# MCASP3_CFG register map
Vendor: Texas Instruments
Registers are 32-bit, read-write, reset values left out (the file's numbers can be read two ways) unless marked. A register's access mark holds for its fields unless they carry their own. Offsets are as the file gives them; [hi:lo] are bit positions; {n}, {i} and the like mark numbered series; 'fields as' and 'values as' point back to an identical list.

## MCASP3_CFG (part 2 of 2)
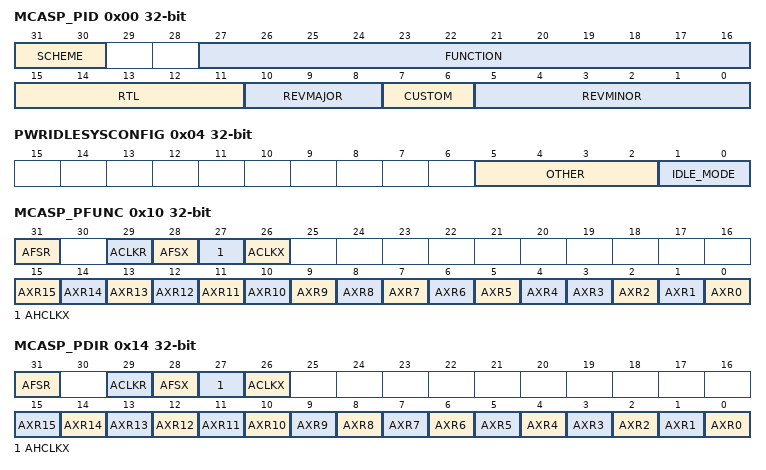
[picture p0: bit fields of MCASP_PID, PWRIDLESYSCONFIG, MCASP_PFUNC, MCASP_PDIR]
0x00 MCASP_PID ro — Peripheral identification register
  [31:30] SCHEME — Scheme. Distinguishes between old scheme and current.
  [27:16] FUNCTION — MCASP. Indicates a software-compatible module family.
  [15:11] RTL — RTL version.
  [10:8] REVMAJOR — Major revision number.
  [7:6] CUSTOM — Non-custom. Indicates a special version for a given device.
  [5:0] REVMINOR — Minor revision number.
0x04 PWRIDLESYSCONFIG access per field — Power idle module configuration register.
  [5:2] OTHER rw — Reserved for future expansion
  [1:0] IDLE_MODE rw — 0x0: Force-idle mode 0x1: No-idle mode 0x2: Smart-idle mode - default state 0x3: Reserved
0x10 MCASP_PFUNC — Specifies the function of the pins as either a MCASP pin or a GPIO pin
  [31] AFSR — Determines if AFSR pin (device level MCASPi_fsr signal) functions as MCASP or GPIO.
    0=Pin_functions_as_MCASP_pin; 1=Pin_functions_as_GIO_pin
  [29] ACLKR — Determines if ACLKR pin (device level MCASPi_aclkr signal) functions as MCASP or GPIO.
    0=Pin_functions_as_MCASP_pin; 1=Pin_functions_as_GIO_pin
  [28] AFSX — Determines if AFSX pin (device level MCASPi_fsx signal) functions as MCASP or GPIO.
    0=GPIO (Pin functions as MCASP pin); 1=Pin_functions_as_GIO_pin
  [27] AHCLKX — Determines if AHCLKX pin (device level MCASPi_ahclkx signal) functions as MCASP or GPIO.
    values as AFSX
  [26] ACLKX — Determines if ACLKX pin (device level MCASPi_aclkx signal) functions as MCASP or GPIO.
    values as AFSX
  [n] AXR{n} (n=4..15) — Determines if AXR{n} pin (device level MCASPx_axr[{n}] signal) functions as MCASP or GPIO.
    0=Pin_functions_as_MCASP_pin; 1=Pin_functions_as_GIO_pin
  [3] AXR3 — Determines if AXR3 pin (device level MCASPi_axr[3] signal) functions as MCASP or GPIO.
    0=Pin_functions_as_MCASP_pin; 1=Pin_functions_as_GIO_pin
  [2] AXR2 — Determines if AXR2 pin (device level MCASPi_axr[2] signal) functions as MCASP or GPIO.
    0=Pin_functions_as_MCASP_pin; 1=Pin_functions_as_GIO_pin
  [1] AXR1 — Determines if AXR1 pin (device level MCASPi_axr[1] signal) functions as MCASP or GPIO.
    0=Pin_functions_as_MCASP_pin; 1=Pin_functions_as_GIO_pin
  [0] AXR0 — Determines if AXR0 pin (device level MCASPi_axr[0] signal) functions as MCASP or GPIO.
    values as AFSX
0x14 MCASP_PDIR — Pin direction register - specifies the direction of the MCASP pins as either an input or an output pin.
  [31] AFSR — Determines if AFSR pin (device level MCASPi_fsr signal) functions as an input or output.
    0=Input; 1=Output
  [29] ACLKR — Determines if ACLKR pin (device level MCASPi_aclkr signal) functions as an input or output.
    0=Input; 1=Output
  [28] AFSX — Determines if AFSX pin (device level MCASPi_fsx signal) functions as an input or output.
    0=OUTPUT (Input); 1=Output
  [27] AHCLKX — Determines if AHCLKX pin (device level MCASPi_ahclkx signal) functions as an input or output.
    0=OUTPUT (Input); 1=Output
  [26] ACLKX — Determines if ACLKX pin (device level MCASPi_aclkx signal) functions as an input or output.
    0=OUTPUT (Input); 1=Output
  [n] AXR{n} (n=1..15) — Determines if AXR{n} pin (device level MCASPi_axr[{n}] signal) functions as an input or output.
    0=Input; 1=Output
  [0] AXR0 — Determines if AXR0 pin (device level MCASPi_axr[0] signal) functions as an input or output.
    0=OUTPUT (Input); 1=Output
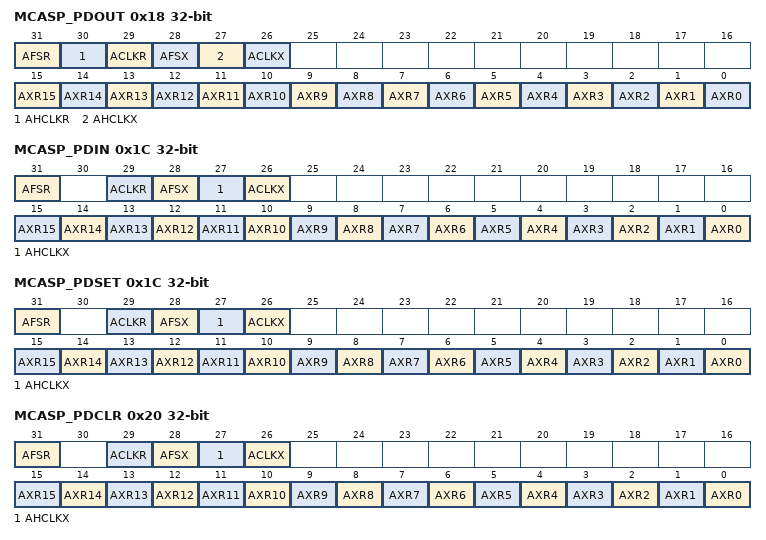
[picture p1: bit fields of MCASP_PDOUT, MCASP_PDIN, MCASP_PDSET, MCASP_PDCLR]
0x18 MCASP_PDOUT — Pin data output register - holds a value for data out at all times, and may be read back at all times. The value held by is not affected by writing to and . However, the data value in is driven out onto the MCASP pin only if the corresponding bit in is set to 1 (GPIO function) and the corresponding bit in is set to 1 (output).
  [31] AFSR — Determines drive on AFSR output pin when the correspondingMCASP_PFUNC[31] and MCASP_PDIR[31] bits are set to 1.
    0=The_pin_drives_low; 1=The_pin_drives_high
  [30] AHCLKR — Determines drive on AHCLKR output pin when the correspondingMCASP_PFUNC[30] and MCASP_PDIR[30] bits are set to 1.
    0=The_pin_drives_low; 1=The_pin_drives_high
  [29] ACLKR — Determines drive on ACLKR output pin when the correspondingMCASP_PFUNC[29] and MCASP_PDIR[29] bits are set to 1
    0=The_pin_drives_low; 1=The_pin_drives_high
  [28] AFSX — Determines drive on AFSX output pin when the correspondingMCASP_PFUNC[28] and MCASP_PDIR[28] bits are set to 1.
    0=DRV1 (The pin drives low.); 1=The_pin_drives_high
  [27] AHCLKX — Determines drive on AHCLKX output pin when the correspondingMCASP_PFUNC[27] and MCASP_PDIR[27] bits are set to 1.
    0=DRV1 (The pin drives low.); 1=The_pin_drives_high
  [26] ACLKX — Determines drive on ACLKX output pin when the correspondingMCASP_PFUNC[26] and MCASP_PDIR[26] bits are set to 1
    0=DRV1 (The pin drives low.); 1=The_pin_drives_high
  [n] AXR{n} (n=1..15) — Determines drive on AXR{n} output pin when the correspondingMCASP_PFUNC[{n}] and MCASP_PDIR[{n}] bits are set to 1.
    0=The_pin_drives_low; 1=The_pin_drives_high
  [0] AXR0 — Determines drive on AXR0 output pin when the correspondingMCASP_PFUNC[0] and MCASP_PDIR[0] bits are set to 1.
    0=DRV1 (The pin drives low.); 1=The_pin_drives_high
0x1C MCASP_PDIN ro — Pin data input register - holds the state of all the MCASP pins. allows reading the actual value of the pin, regardless of the state of and .
  [31] AFSR — Logic level on AFSR pin (device level MCASPi_fsr signal).
    0=Pin_is_logic_low; 1=Pin_is_logic_high
  [29] ACLKR — Logic level on ACLKR pin (device level MCASPi_aclkr signal).
    0=Pin_is_logic_low; 1=Pin_is_logic_high
  [28] AFSX — Logic level on AFSX pin (device level MCASPi_fsx signal).
    0=LOW (Pin is logic low.); 1=Pin_is_logic_high
  [27] AHCLKX — Logic level on AHCLKX pin (device level MCASPi_ahclkx signal).
    0=LOW (Pin is logic low.); 1=Pin_is_logic_high
  [26] ACLKX — Logic level on ACLKX pin (device level MCASPi_aclkx signal).
    0=LOW (Pin is logic low.); 1=Pin_is_logic_high
  [n] AXR{n} (n=1..15) — Logic level on AXR{n} pin (device level MCASPi_axr[{n}] signal).
    0=Pin_is_logic_low; 1=Pin_is_logic_high
  [0] AXR0 — Logic level on AXR0 pin (device level MCASPi_axr[0] signal).
    0=LOW (Pin is logic low.); 1=Pin_is_logic_high
0x1C MCASP_PDSET wo — The pin data set register is an alias of the pin data output register () for writes only. Writing a 1 to the bit sets the corresponding bit in and, if = 1 (GPIO function) and = 1 (output), drives a logic high on the pin.
  [31] AFSR — Allows the corresponding AFSR bit inMCASP_PDOUT to be set to a logic high without affecting other I/O pins controlled by the same port.
    0=No_effect; 1=[31]_bit_is_set_to_1
  [29] ACLKR — Allows the corresponding ACLKR bit inMCASP_PDOUT to be set to a logic high without affecting other I/O pins controlled by the same port.
    0=No_effect; 1=[29]_bit_is_set_to_1
  [28] AFSX — Allows the corresponding AFSX bit inMCASP_PDOUT to be set to a logic high without affecting other I/O pins controlled by the same port.
    0=SET (No effect); 1=[28]_bit_is_set_to_1
  [27] AHCLKX — Allows the corresponding AHCLKX bit inMCASP_PDOUT to be set to a logic high without affecting other I/O pins controlled by the same port.
    0=SET (No effect); 1=[27]_bit_is_set_to_1
  [26] ACLKX — Allows the corresponding ACLKX bit inMCASP_PDOUT to be set to a logic high without affecting other I/O pins controlled by the same port.
    0=SET (No effect); 1=[26]_bit_is_set_to_1
  [n] AXR{n} (n=1..15) — Allows the AXR{n} bit inMCASP_PDOUT to be set to a logic high without affecting other I/O pins controlled by the same port.
    0=No_effect; 1=[{n}]_bit_is_set_to_1
  [0] AXR0 — Allows the AXR0 bit inMCASP_PDOUT to be set to a logic high without affecting other I/O pins controlled by the same port.
    0=SET (No effect); 1=[0]_bit_is_set_to_1
0x20 MCASP_PDCLR — The pin data clear register is an alias of the pin data output register () for writes only. Writing a 1 to the bit clears the corresponding bit in and, if = 1 (GPIO function) and = 1 (output), drives a logic low on the pin.
  [31] AFSR — Allows the corresponding AFSR bit inMCASP_PDOUT to be cleared to a logic low without affecting other I/O pins controlled by the same port.
    0=No_effect; 1=[31]_bit_is_cleared_to_0
  [29] ACLKR — Allows the corresponding ACLKR bit inMCASP_PDOUT to be cleared to a logic low without affecting other I/O pins controlled by the same port.
    0=No_effect; 1=[29]_bit_is_cleared_to_0
  [28] AFSX — Allows the corresponding AFSX bit inMCASP_PDOUT to be cleared to a logic low without affecting other I/O pins controlled by the same port.
    0=CLEAR (No effect); 1=[28]_bit_is_cleared_to_0
  [27] AHCLKX — Allows the corresponding AHCLKX bit inMCASP_PDOUT to be cleared to a logic low without affecting other I/O pins controlled by the same port.
    0=CLEAR (No effect); 1=[27]_bit_is_cleared_to_0
  [26] ACLKX — Allows the corresponding ACLKX bit inMCASP_PDOUT to be cleared to a logic low without affecting other I/O pins controlled by the same port.
    0=CLEAR (No effect); 1=[26]_bit_is_cleared_to_0
  [n] AXR{n} (n=1..15) — Allows the AXR{n} bit inMCASP_PDOUT to be cleared to a logic low without affecting other I/O pins controlled by the same port.
    0=No_effect; 1=[{n}]_bit_is_cleared_to_0
  [0] AXR0 — Allows the AXR0 bit inMCASP_PDOUT to be cleared to a logic low without affecting other I/O pins controlled by the same port.
    0=CLEAR (No effect); 1=[0]_bit_is_cleared_to_0
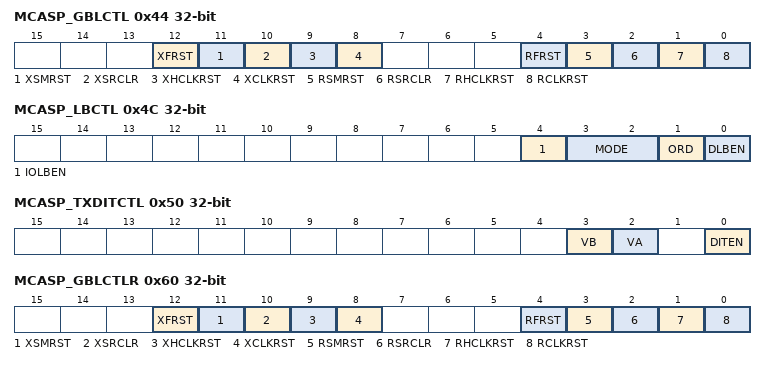
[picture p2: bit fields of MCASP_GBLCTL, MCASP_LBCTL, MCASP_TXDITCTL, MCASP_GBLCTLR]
0x44 MCASP_GBLCTL — Global transmit control register - provides initialization of the transmit and receive sections. The bit fields in are synchronized and latched by the transmitter and receiver corresponding clocks - MCASPi_aclkx clock ( bits [12:8] ) and MCASPi_aclkr ( bits [4:0] ), respectively. Before programming , ensure that the serial clocks are running. If the corresponding external serial clocks - MCASPi_aclkx and MCASPi_aclkr, are not yet running, select the internal serial clock source in AHCLKXCTL, AHCLKRCTL, ACLKXCTL and ACLKRCTL before programming the . Also, after programming any bits in , do not proceed until reading back from and verifying that the bits in are latched.
  [12] XFRST — Transmit frame-sync generator reset enable bit
    0=RESET (The transmit frame-sync generator is reset.); 1=ACTIVE (The transmit frame-sync generator is active. When released from reset, the transmit frame-sync generator begins counting serial clocks and generating frame sync as programmed.)
  [11] XSMRST — Transmit state-machine reset enable bitAXR[n] pin state : If[n] = 0 and [n] = 1, the corresponding serializer [n] drives the AXR[n] pin to the state specified for inactive time slot. .
    0=RESET (The transmit state-machine is held in reset.); 1=ACTIVE (The transmit state-machine is released from reset. When released from reset, the transmit state-machine immediately transfers data from XBUF[n] to XRSR[n]. The transmit state-machine sets the underrun flag (XUNDRN) in MCASP_XSTAT, if XBUF[n] have not been preloaded with data before reset is released. The transmit state-machine also immediately begins detecting frame sync and is ready to transmit. Transmission of TDM time slot begins at slot 0 after reset is released.)
  [10] XSRCLR — Transmit serializer clear enable bit. By clearing and then setting this bit, the transmit buffer is flushed to an empty state (XDATA = 1). If XSMRST = 1, XSRCLR = 1, XDATA = 1, and XBUF is not loaded with new data before the start of the next active time slot, an underrun occurs.
    0=CLEAR (The transmit serializer is cleared.); 1=ACTIVE (The transmit serializer is active. When the transmit serializer is first taken out of reset (XSRCLR changes from 0 to 1), the transmit data ready bit (XDATA) in MCASP_XSTAT is set to indicate XBUF is ready to be written.)
  [9] XHCLKRST — Transmit high-frequency clock divider reset enable bit
    0=RESET (The transmitter high-frequency clock divider is held in reset and passes through its input as divide-by-1.); 1=ACTIVE (The transmitter high-frequency clock divider is running.)
  [8] XCLKRST — Transmit clock divider reset enable bit
    0=RESET (The transmit clock divider is held in reset. When the clock divider is in reset, it passes through a divide-by-1 of its input.); 1=ACTIVE (The transmit clock divider is running.)
  [4] RFRST — Receive frame sync generator reset enable bit.
    0=RESET (Receive frame sync generator is reset.); 1=ACTIVE (Receive frame sync generator is active. When released from reset, the receive frame sync generator begins counting serial clocks and generating frame sync as programmed.)
  [3] RSMRST — Receive state machine reset enable bit.
    0=RESET (Receive state machine is held in reset.); 1=ACTIVE (Receive state machine is released from reset. When released from reset, the receive state machine immediately begins detecting frame sync and is ready to receive. Receive TDM time slot begins at slot 0 after reset is released.)
  [2] RSRCLR — Receive serializer clear enable bit. By clearing then setting this bit, the receive buffer is flushed.
    0=CLEAR (Receive serializers are cleared.); 1=ACTIVE (Receive serializers are active.)
  [1] RHCLKRST — Receive high-frequency clock divider reset enable bit.
    0=RESET (Receive high-frequency clock divider is held in reset and passes through its input as divide-by-1.); 1=ACTIVE (Receive high-frequency clock divider is running.)
  [0] RCLKRST — Receive clock divider reset enable bit.
    0=RESET (Receive clock divider is held in reset. When the clock divider is in reset, it passes through a divide-by-1 of its input.); 1=ACTIVE (Receive clock divider is running.)
0x48 MCASP_AMUTE — Mute control register - Controls the MCASP mute output pin - AMUTE (device level - not implemented)
0x4C MCASP_LBCTL — The digital loopback control register () controls the internal (MCASP module)- level and chip-level loopback settings of the MCASP in TDM mode. Note that loopback is NOT supported if MCASP is configured in DIT mode.
  [4] IOLBEN — If DLBEN=0b1, the IOLBEN bit selects between and loopback modes. IOLBEN bit value is irrelevant, If DLBEN=0b0.
    0=INTERNAL_LB (MCASP internal loopback mode enabled. This selects a direct loopback between corresponding MCASP AXRn and AXRn+1 pins, bypassing device pad I/O buffers.); 1=CHIP_LB (Chip I/O-level loopback mode enabled. The MCASP data is looped back through the device pad I/O buffers.)
  [3:2] MODE — Loopback generator mode bits.0x2, 0x3: Reserved enum=RESERVED .
    0=NO_LOOPBACK (RESERVED); 1=LOOPBACK (MODE must be set to 0x1 when MCASP operates in loopback mode (DLBEN =0b1). This is necessary to allow transmit clock and frame sync generators to be used by both transmit and receive sections.)
  [1] ORD — Loopback order bit when loopback mode is enabled (DLBEN = 1).
    0=ODD (Odd serializers N + 1 transmit to even serializers N that receive. The corresponding serializers must be programmed properly.); 1=EVEN (Even serializers N transmit to odd serializers N+1 that receive. The corresponding serializers must be programmed properly.)
  [0] DLBEN — Loop back mode enable bit.
    0=DISABLE (Loop back mode is disabled (normal MCASP operation).); 1=ENABLE (Loop back is enabled (TDM mode only). Loopback type is selected in IOLBEN bit.)
0x50 MCASP_TXDITCTL — Transmit DIT mode control register, controls DIT operations of the MCASP
  [3] VB — Valid bit for odd time slots (DIT right subframe).
    0=ONESTUFF (V bit is 0 during odd DIT subframes.); 1=V_bit_is_1_during_odd_DIT_subframes
  [2] VA — Valid bit for even time slots (DIT left subframe).
    0=ONESTUFF (V bit is 0 during even DIT subframes.); 1=V_bit_is_1_during_even_DIT_subframes
  [0] DITEN — DIT mode enable bit
    0=I2S (DIT mode is disabled.); 1=DIT (DIT mode is enabled. Transmitter operates in DIT encoded mode.)
0x60 MCASP_GBLCTLR access per field — Alias of GBLCTL. When writing to this register, only the TRANSMIT bits of GBLCTL are affected (This means GBLCTL bits 8,9,10,11,12). Reads return GBLCTL
  [12] XFRST ro — Frame sync generator reset
    0=RESET; 1=ACTIVE
  [11] XSMRST ro — XMT state machine reset
    0=RESET; 1=ACTIVE
  [10] XSRCLR ro — XMT serializer clear
    0=CLEAR; 1=ACTIVE
  [9] XHCLKRST ro — XMT High Freq. clk Divider
    0=RESET; 1=ACTIVE
  [8] XCLKRST ro — XMT clock divder reset
    0=RESET; 1=ACTIVE
  [4] RFRST rw — Frame sync generator reset
    0=RESET; 1=ACTIVE
  [3] RSMRST rw — RCV state machine reset
    0=RESET; 1=ACTIVE
  [2] RSRCLR rw — RCV serializer clear
    0=CLEAR; 1=ACTIVE
  [1] RHCLKRST rw — RCV High Freq. clk Divider
    0=RESET; 1=ACTIVE
  [0] RCLKRST rw — RCV clock divder reset
    0=RESET; 1=ACTIVE
0x64 MCASP_RXMASK — The receive format unit bit mask register () determines which bits of the received data are masked off and padded with a known value before being read by the CPU.
  [31:0] RMASK_31_0 — Receive data mask enable bit.
    0=USEMASK (Corresponding bit of receive data (after passing through reverse and rotate units) is masked out and then padded with the selected bit pad value (RPAD and RPBIT bits in RFMT).); 1=NOMASK (Corresponding bit of receive data (after passing through reverse and rotate units) is returned to CPU or DMA.)
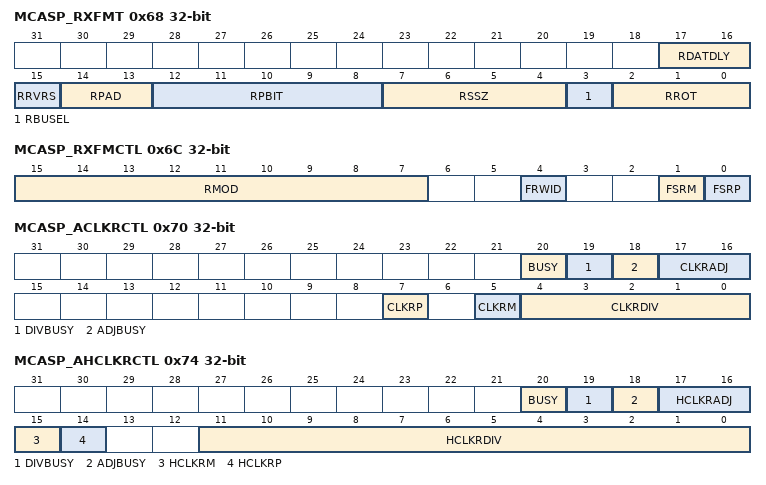
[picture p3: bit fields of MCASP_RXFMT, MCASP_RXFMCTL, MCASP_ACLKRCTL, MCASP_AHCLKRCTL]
0x68 MCASP_RXFMT — The receive bit stream format register () configures the receive data format.
  [17:16] RDATDLY — Receive Frame sync delay of AXR[n]
    0=0BIT (0-bit delay. The first receive data bit, AXR[n], occurs in same ACLKR cycle as the receive frame sync (AFSR).); 1=1BIT (1-bit delay. The first receive data bit, AXR[n], occurs one ACLKR cycle after the receive frame sync (AFSR).); 2=2BIT (2-bit delay. The first receive data bit, AXR[n], occurs two ACLKR cycles after the receive frame sync (AFSR).); 3=2BIT (Reserved)
  [15] RRVRS — Receive serial bitstream order
    0=LSBFIRST (Bitstream is LSB first. No bit reversal is performed in receive format bit reverse unit.); 1=MSBFIRST (Bitstream is MSB first. Bit reversal is performed in receive format bit reverse unit.)
  [14:13] RPAD — Pad value for extra bits in slot not belonging to the word. This field only applies to bits when RMASK[n] = 0.
    0=ZERO (Pad extra bits with 0.); 1=ONE (Pad extra bits with 1.); 2=RPBIT (Pad extra bits with one of the bits from the word as specified by RPBIT bits.); 3=RPBIT (Reserved)
  [12:8] RPBIT — RPBIT value determines which bit (as read by the CPU from RBUF[n]) is used to pad the extra bits. This field only applies when RPAD = 2h.0x01 - 0x1F: Pad with value of the bit positioned within the range RBUFn[31:1]. .
    0=Pad_with_value_of_bit_RBUFn[0]
  [7:4] RSSZ — Receive slot size.0x0 - 0x2 : Reserved enum=RSVD .
    3=8BITS (Slot size is 8 bits); 5=12BITS (Slot size is 12 bits); 7=16BITS (Slot size is 16 bits); 9=20BITS (Slot size is 20 bits); 11=24BITS (Slot size is 24 bits); 13=28BITS (Slot size is 28 bits); 14=32BITS (Reserved); 15=32BITS (Slot size is 32 bits)
  [3] RBUSEL — Selects whether reads from serializer buffer RBUF[n] originate from the peripheral configuration CFG port or the DATA port.
    0=VBUSP (Reads from XRBUF[n] originate on DATA port. Reads from XRBUF[n] on the peripheral configuration port are ignored.); 1=VBUS (Reads from XRBUF[n] originate on peripheral configuration port. Reads from XRBUF[n] on the DATA port are ignored.)
  [2:0] RROT — Right-rotation value for receive rotate right format unit.
    0=NONE (Rotate right by 0 (no rotation).); 1=4BITS (Rotate right by 4 bit positions.); 2=8BITS (Rotate right by 8 bit positions.); 3=12BITS (Rotate right by 12 bit positions.); 4=16BITS (Rotate right by 16 bit positions.); 5=20BITS (Rotate right by 20 bit positions.); 6=24BITS (Rotate right by 24 bit positions.); 7=28BITS (Rotate right by 28 bit positions.)
0x6C MCASP_RXFMCTL — The receive frame sync control register () configures the receive frame sync (AFSR).
  [15:7] RMOD — Receive frame sync mode select bits.0x3 - 0x20: 3-slot TDM to 32-slot TDM mode . 0x21 - 0x17F: Reserved . 0x181 - 0x1FF: Reserved .
    0=Burst_mode; 2=2-slot_TDM_mode(_I2S_receive_mode); 0x180=TDM_DIR_IC_DIR_MCASP)_384 (384-slot TDM (external DIR IC inputting 384-slot DIR frames to MCASP))
  [4] FRWID — Receive frame sync width select bit indicates the width of the receive frame sync (AFSR) during its active period.
    0=BIT (Single bit); 1=WORD (Single word. Single word is not supported if RMOD is set to burst mode.)
  [1] FSRM — Receive frame sync generation select bit.
    0=EXTERNAL (Externally-generated receive frame sync); 1=INTERNAL (Internally-generated receive frame sync)
  [0] FSRP — Receive frame sync polarity select bit.
    0=RISINGEDGE (A rising edge on receive frame sync (AFSR) indicates the beginning of a frame.); 1=FALLINGEDGE (A falling edge on receive frame sync (AFSR) indicates the beginning of a frame.)
0x70 MCASP_ACLKRCTL access per field — The receive clock control register () configures the receive bit clock (ACLKR) and the receive clock generator.
  [20] BUSY rw — Status: logical OR of DIVBUSY, ADJBUSY. Not supported.
    0=NOTBUSY; 1=BUSY
  [19] DIVBUSY rw — Status: divide ratio change in progress? Not supported.
    0=NOTBUSY; 1=BUSY
  [18] ADJBUSY rw — Status: one-shot adjustment in progress? Not supported.
    0=NOTBUSY; 1=BUSY
  [17:16] CLKRADJ wo — CLKRDIV one-shot adjustment. Not supported. Bit field must always be written as 0x0.If CLKRDIV is set such that there are “m” input clocks per one output clock, then for one output cycle:00 = (m+0) input clocks per output clock, i.e. no adjustment . 01 = (m-1) input clocks per output clock . 10 = (m+1) input clocks per output clock . 11 = (m+0) input clocks per output clock, i.e. no adjustment . NOTE: writes to these bits are ineffective if CLKADJEN:ENABLE bit is set to 0b. These bits are ALWAYS read back as zero. .
  [7] CLKRP rw — Receive bitstream clock polarity select bit. Note that this bitfield does not have any effect, ifMCASP_ACLKXCTL[6] ASYNC = 0
    0=FALLINGEDGE (Falling edge. Receiver samples data on the falling edge of the serial clock, so the external transmitter driving this receiver must shift data out on the rising edge of the serial clock.); 1=RISINGEDGE (Rising edge. Receiver samples data on the rising edge of the serial clock, so the external transmitter driving this receiver must shift data out on the falling edge of the serial clock.)
  [5] CLKRM rw — Receive bit clock source bit. Note that this bitfield does not have any effect, ifMCASP_ACLKXCTL[6] ASYNC = 0
    0=EXTERNAL (External receive clock source from ACLKR pin.); 1=INTERNAL (Internal receive clock source from output of programmable bit clock divider.)
  [4:0] CLKRDIV rw — Receive bit clock divide ratio bits determine the divide-down ratio from AHCLKR to ACLKR. Note that this bitfield does not have any effect, ifMCASP_ACLKXCTL[6] ASYNC = 0.0x2 - 0x1F: Divide-by-3 to divide-by-32 .
    0=Divide-by-1; 1=Divide-by-2
0x74 MCASP_AHCLKRCTL access per field — The receive high-frequency clock control register () configures the receive high-frequency master clock (AHCLKR) and the receive clock generator.
  [20] BUSY rw — Status: logical OR of DIVBUSY, ADJBUSY. Not supported.
    0=NOTBUSY; 1=BUSY
  [19] DIVBUSY rw — Status: divide ratio change in progress? Not supported.
    0=NOTBUSY; 1=BUSY
  [18] ADJBUSY rw — Status: one-shot adjustment in progress? Not supported.
    0=NOTBUSY; 1=BUSY
  [17:16] HCLKRADJ wo — HCLKRDIV one-shot adjustment. Not supported. Bit field must always be written as 0x0. If HCLKRDIV is set such that there are “m” input clocks per one output clock, then for one output cycle:00 = (m+0) input clocks per output clock, i.e. no adjustment . 01 = (m-1) input clocks per output clock . 10 = (m+1) input clocks per output clock . 11 = (m+0) input clocks per output clock, i.e. no adjustment . NOTE: writes to these bits are ineffective if CLKADJEN:ENABLE bit is set to 0b. These bits are ALWAYS read back as zero. .
  [15] HCLKRM rw — High Freq. RCV clock Source
    0=EXTERNAL; 1=INTERNAL
  [14] HCLKRP rw — Receive bitstream high-frequency clock polarity select bit.
    0=NOTINVERTED (Not inverted. AHCLKR is not inverted before programmable bit clock divider.); 1=INVERTED (Inverted. AHCLKR is inverted before programmable bit clock divider.)
  [11:0] HCLKRDIV rw — Receive high-frequency clock divide ratio bits determine the divide-down ratio from AUXCLK to AHCLKR.0x2 - 0xFFF: Divide-by-3 to divide-by-4096 .
    0=Divide-by-1; 1=Divide-by-2
0x78 MCASP_RXTDM — The receive TDM time slot register () specifies which TDM time slot the receiver is active.
  [31:0] RTDMS_31_0 — Receiver mode during TDM time slot n.
    0=INACTIVE (Receive TDM time slot n is inactive. The receive serializer does not shift in data during this slot.); 1=ACTIVE (Receive TDM time slot n is active. The receive serializer shifts in data during this slot.)
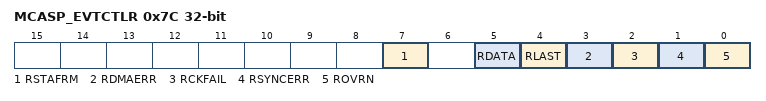
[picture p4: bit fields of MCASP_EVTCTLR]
0x7C MCASP_EVTCTLR — Receiver Interrupt control register - controls generation of the MCASP receive interrupt (RINT). When the register bit(s) is set to 1, the occurrence of the enabled MCASP condition(s) generates RINT.
  [7] RSTAFRM — Receive start of frame interrupt enable bit
    0=ENABLE (Interrupt is disabled. A receive-start-of-frame interrupt does not generate a MCASP receive interrupt (RINT).); 1=A_MCASP_(RINT)._1 (Interrupt is enabled. A receive-start-of-frame interrupt generates a MCASP receive interrupt (RINT).)
  [5] RDATA — Receive data-ready interrupt enable bit
    0=ENABLE (Interrupt is disabled. A receive data-ready interrupt does not generate a MCASP receive interrupt (RINT).); 1=A_MCASP_(RINT)._1 (Interrupt is enabled. A receive data-ready interrupt generates a MCASP receive interrupt (RINT).)
  [4] RLAST — Receive last slot interrupt enable bit
    0=ENABLE (Interrupt is disabled. A receive-last-slot interrupt does not generate a MCASP receive interrupt (RINT).); 1=A_MCASP_(RINT)._1 (Interrupt is enabled. A receive-last-slot interrupt generates a MCASP receive interrupt (RINT).)
  [3] RDMAERR — Receive DMA error interrupt enable bit
    0=ENABLE (Interrupt is disabled. A receive DMA error interrupt does not generate a MCASP receive interrupt (RINT).); 1=A_DMA_MCASP_(RINT)._1 (Interrupt is enabled. A receive DMA error interrupt generates a MCASP receive interrupt (RINT).)
  [2] RCKFAIL — Receive clock failure interrupt enable bit
    0=ENABLE (Interrupt is disabled. A receive clock failure interrupt does not generate a MCASP receive interrupt (RINT).); 1=A_MCASP_(RINT)._1 (Interrupt is enabled. A receive clock failure interrupt generates a MCASP receive interrupt (RINT).)
  [1] RSYNCERR — Unexpected receive frame-sync interrupt enable bit
    0=ENABLE (Interrupt is disabled. An unexpected receive frame-sync interrupt does not generate a MCASP receive interrupt (RINT).); 1=MCASP_(RINT)._1 (Interrupt is enabled. An unexpected receive frame-sync interrupt generates a MCASP receive interrupt (RINT).)
  [0] ROVRN — Receiver overrun interrupt enable bit
    0=ENABLE (Interrupt is disabled. A receiver overrun interrupt does not generate a MCASP receive interrupt (RINT).); 1=A_MCASP_(RINT)._1 (Interrupt is enabled. A receiver overrun interrupt generates a MCASP receive interrupt (RINT).)
